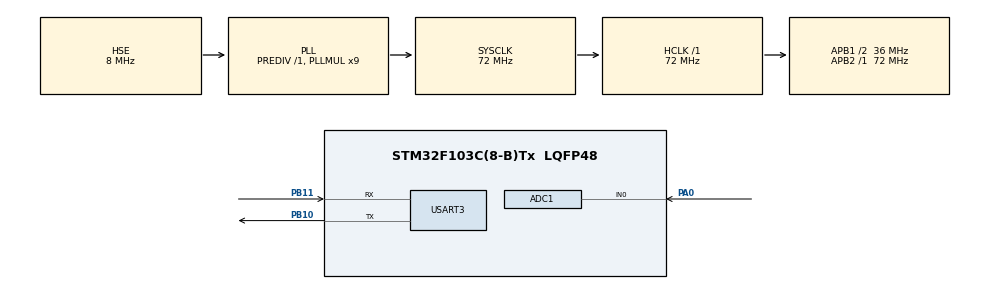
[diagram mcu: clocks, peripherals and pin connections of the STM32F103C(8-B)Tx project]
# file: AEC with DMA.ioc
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ADC1.Channel-0\#ChannelRegularConversion=ADC_CHANNEL_0
ADC1.ContinuousConvMode=ENABLE
ADC1.NbrOfConversionFlag=1
ADC1.Rank-0\#ChannelRegularConversion=1
ADC1.SamplingTime-0\#ChannelRegularConversion=ADC_SAMPLETIME_71CYCLES_5
ADC1.master=1
Dma.ADC1.0.Direction=DMA_PERIPH_TO_MEMORY
Dma.ADC1.0.Instance=DMA1_Channel1
Dma.ADC1.0.MemDataAlignment=DMA_MDATAALIGN_HALFWORD
Dma.ADC1.0.MemInc=DMA_MINC_ENABLE
Dma.ADC1.0.Mode=DMA_CIRCULAR
Dma.ADC1.0.PeriphDataAlignment=DMA_PDATAALIGN_HALFWORD
Dma.ADC1.0.PeriphInc=DMA_PINC_DISABLE
Dma.ADC1.0.Priority=DMA_PRIORITY_LOW
Dma.Request0=ADC1
Mcu.Family=STM32F1
Mcu.Name=STM32F103C(8-B)Tx
Mcu.Package=LQFP48
NVIC.DMA1_Channel1_IRQn=true\:0\:0\:false\:false\:true\:false\:true
NVIC.PriorityGroup=NVIC_PRIORITYGROUP_4
PA0-WKUP.Signal=ADCx_IN0
PA13.Mode=Serial_Wire
PA13.Signal=SYS_JTMS-SWDIO
PA14.Mode=Serial_Wire
PA14.Signal=SYS_JTCK-SWCLK
PB10.Mode=Asynchronous
PB10.Signal=USART3_TX
PB11.Mode=Asynchronous
PB11.Signal=USART3_RX
PD0-OSC_IN.Mode=HSE-External-Oscillator
PD0-OSC_IN.Signal=RCC_OSC_IN
PD1-OSC_OUT.Mode=HSE-External-Oscillator
PD1-OSC_OUT.Signal=RCC_OSC_OUT
ProjectManager.HeapSize=0x200
ProjectManager.StackSize=0x400
ProjectManager.TargetToolchain=MDK-ARM V5.27
RCC.ADCPresc=RCC_ADCPCLK2_DIV6
RCC.AHBFreq_Value=72000000
RCC.APB1CLKDivider=RCC_HCLK_DIV2
RCC.APB1Freq_Value=36000000
RCC.APB1TimFreq_Value=72000000
RCC.APB2Freq_Value=72000000
RCC.APB2TimFreq_Value=72000000
RCC.HCLKFreq_Value=72000000
RCC.PLLMUL=RCC_PLL_MUL9
RCC.PLLSourceVirtual=RCC_PLLSOURCE_HSE
RCC.SYSCLKFreq_VALUE=72000000
RCC.SYSCLKSource=RCC_SYSCLKSOURCE_PLLCLK
RCC.USBFreq_Value=72000000
SH.ADCx_IN0.0=ADC1_IN0,IN0
USART3.VirtualMode=VM_ASYNC
board=custom

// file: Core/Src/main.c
/* USER CODE BEGIN Header */
/**
  ******************************************************************************
  * @file           : main.c
  * @brief          : Main program body
  ******************************************************************************
  * @attention
  *
  * <h2><center>&copy; Copyright (c) 2021 STMicroelectronics.
  * All rights reserved.</center></h2>
  *
  * This software component is licensed by ST under BSD 3-Clause license,
  * the "License"; You may not use this file except in compliance with the
  * License. You may obtain a copy of the License at:
  *                        opensource.org/licenses/BSD-3-Clause
  *
  ******************************************************************************
  */
/* USER CODE END Header */
#include "main.h"
#include "adc.h"
#include "dma.h"
#include "usart.h"
#include "gpio.h"

/* USER CODE BEGIN Includes */
#include <stdio.h>
/* USER CODE END Includes */

/* USER CODE BEGIN PD */
#define DEBUG
/* USER CODE END PD */

/* USER CODE BEGIN PV */
uint32_t adc_val;
char str[12];
/* USER CODE END PV */

void SystemClock_Config(void);
/* USER CODE BEGIN PFP */
/* printf --> huart3 for debugging */
struct __FILE{
  int handle;
  /* Whatever you require here. If the only file you are using is */
  /* standard output using printf() for debugging, no file handling */
  /* is required. */
};

FILE __stdout;

int fputc(int ch, FILE *f){
   HAL_UART_Transmit(&huart3, (uint8_t *)&ch, 1, 0xFFFF);
  return ch;
}

int ferror(FILE *f){
  /* Your implementation of ferror(). */
  return 0;
}
/* USER CODE END PFP */

int main(void)
{

  /* MCU Configuration--------------------------------------------------------*/

  /* Reset of all peripherals, Initializes the Flash interface and the Systick. */
  HAL_Init();

  /* Configure the system clock */
  SystemClock_Config();

  /* Initialize all configured peripherals */
  MX_GPIO_Init();
  MX_DMA_Init();
  MX_ADC1_Init();
  MX_USART3_UART_Init();
  /* USER CODE BEGIN 2 */
	HAL_ADC_Start_DMA(&hadc1, &adc_val,1);
  /* USER CODE END 2 */

  /* Infinite loop */
  /* USER CODE BEGIN WHILE */
  while (1)
  {
#ifdef DEBUG
		printf("var: %d\r\n", adc_val);
#endif
	//	sprintf(str, "var: %d\r\n", adc_val);
	//	HAL_UART_Transmit(&huart3, (uint8_t *)str, 12, 10);
		HAL_Delay(100);
    /* USER CODE END WHILE */

  }
}

void SystemClock_Config(void)
{
  RCC_OscInitTypeDef RCC_OscInitStruct = {0};
  RCC_ClkInitTypeDef RCC_ClkInitStruct = {0};
  RCC_PeriphCLKInitTypeDef PeriphClkInit = {0};

  /** Initializes the RCC Oscillators according to the specified parameters
  * in the RCC_OscInitTypeDef structure.
  */
  RCC_OscInitStruct.OscillatorType = RCC_OSCILLATORTYPE_HSE;
  RCC_OscInitStruct.HSEState = RCC_HSE_ON;
  RCC_OscInitStruct.HSEPredivValue = RCC_HSE_PREDIV_DIV1;
  RCC_OscInitStruct.HSIState = RCC_HSI_ON;
  RCC_OscInitStruct.PLL.PLLState = RCC_PLL_ON;
  RCC_OscInitStruct.PLL.PLLSource = RCC_PLLSOURCE_HSE;
  RCC_OscInitStruct.PLL.PLLMUL = RCC_PLL_MUL9;
  if (HAL_RCC_OscConfig(&RCC_OscInitStruct) != HAL_OK)
  {
    Error_Handler();
  }
  /** Initializes the CPU, AHB and APB buses clocks
  */
  RCC_ClkInitStruct.ClockType = RCC_CLOCKTYPE_HCLK|RCC_CLOCKTYPE_SYSCLK
                              |RCC_CLOCKTYPE_PCLK1|RCC_CLOCKTYPE_PCLK2;
  RCC_ClkInitStruct.SYSCLKSource = RCC_SYSCLKSOURCE_PLLCLK;
  RCC_ClkInitStruct.AHBCLKDivider = RCC_SYSCLK_DIV1;
  RCC_ClkInitStruct.APB1CLKDivider = RCC_HCLK_DIV2;
  RCC_ClkInitStruct.APB2CLKDivider = RCC_HCLK_DIV1;

  if (HAL_RCC_ClockConfig(&RCC_ClkInitStruct, FLASH_LATENCY_2) != HAL_OK)
  {
    Error_Handler();
  }
  PeriphClkInit.PeriphClockSelection = RCC_PERIPHCLK_ADC;
  PeriphClkInit.AdcClockSelection = RCC_ADCPCLK2_DIV6;
  if (HAL_RCCEx_PeriphCLKConfig(&PeriphClkInit) != HAL_OK)
  {
    Error_Handler();
  }
}

void Error_Handler(void)
{
}

/************************ (C) COPYRIGHT STMicroelectronics *****END OF FILE****/
